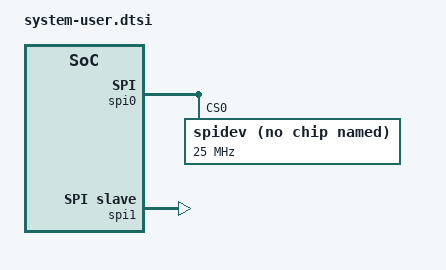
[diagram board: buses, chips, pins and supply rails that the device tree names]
/include/ "system-conf.dtsi"
/ {
};
&spi0{
    status = "okay";
    spidev@0x00 {
        status = "okay";
        // compatible = "xlnx,axi-quad-spi-1.00.a";
        // compatible = "spidev";
        compatible = "rohm,dh2228fv";
        // compatible = "lwn,bk4";
        spi-max-frequency = <25000000>;
        reg = <0>;
    };
};
&spi1{
    status = "okay";
    spi-slave;
    slave {
        compatible = "spi-slave-time";
    };
    spidev@0x01 {
        status = "okay";
        // compatible = "xlnx,axi-quad-spi-1.00.a";
        // compatible = "spidev";
        compatible = "rohm,dh2228fv";
        // compatible = "lwn,bk4";
        spi-max-frequency = <25000000>;
        reg = <0>;
    };
};
